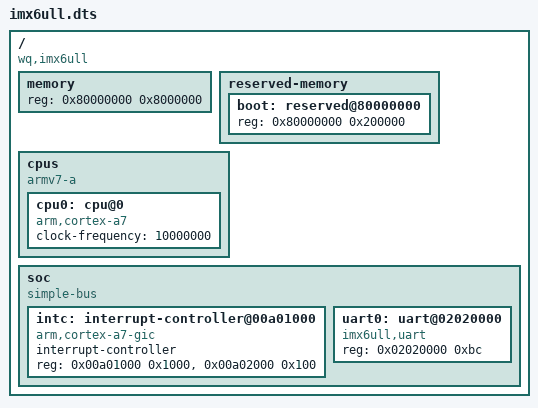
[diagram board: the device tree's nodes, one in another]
/dts-v1/;
/ {
    #address-cells = <1>;
    #size-cells = <1>;
    compatible = "wq,imx6ull";

    memory {
        device_type = "memory";
        reg = < 0x80000000 0x8000000>; 
    };

    reserved-memory {
        #address-cells = <1>;
        #size-cells = <1>;
        ranges;
        boot: reserved@80000000 {
            reg = <0x80000000 0x200000>; // 保留内存区域
        };
    };

    cpus {
        compatible = "armv7-a";
        #address-cells = <1>;
        #size-cells = <1>;
        cpu0: cpu@0 {
            compatible = "arm,cortex-a7";
            device_type = "cpu";
            clock-frequency = <10000000>;
        };
    };

    soc {
        #address-cells = <1>;
        #size-cells = <1>;
        compatible = "simple-bus";

        intc:interrupt-controller@00a01000 {
		compatible = "arm,cortex-a7-gic";
		#interrupt-cells = <3>;
		interrupt-controller;
		reg = <0x00a01000 0x1000>,
		      <0x00a02000 0x100>;
	    };


        // plic: plic@c000000 {
        //     compatible = "riscv,plic";
        //     interrupt-controller;
        //     reg = <0xc000000 0x4000000>;
        //     #interrupt-cells = <1>;
        //     riscv,max-priority = <7>;
        //     riscv,ndev = <53>;       // 支持的外设中断数量
        //     interrupts-extended = <&cpu0 9>; // 通知目标CPU
        // };
       
        // time: time@50000000 {
        //     compatible = "wq,time";
        //     reg = <0x50000000 0x1c>;
        // };
  
        uart0: uart@02020000 {
            compatible = "imx6ull,uart";
            reg = <0x02020000 0xbc>;
            // interrupt-parent = <&plic>;
            // interrupts = <10>;
        };

        // virt_disk: virt_disk@10001000 {
        //     compatible = "wq,virt_disk";
        //     reg = <0x10001000 0x1000>;
        //     interrupt-parent = <&plic>;
        //     interrupts = <11>;
        // };

    };
};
